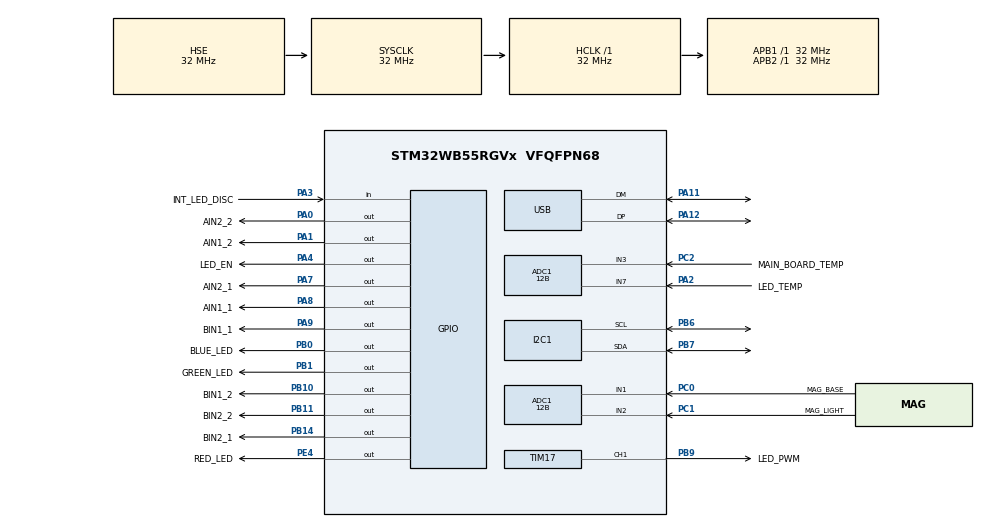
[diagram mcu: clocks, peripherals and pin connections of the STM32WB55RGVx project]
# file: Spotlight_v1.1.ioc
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ADC1.Channel-0\#ChannelRegularConversion=ADC_CHANNEL_1
ADC1.Channel-1\#ChannelRegularConversion=ADC_CHANNEL_2
ADC1.Channel-2\#ChannelRegularConversion=ADC_CHANNEL_3
ADC1.Channel-3\#ChannelRegularConversion=ADC_CHANNEL_7
ADC1.ClockPrescaler=ADC_CLOCK_ASYNC_DIV256
ADC1.ContinuousConvMode=ENABLE
ADC1.DMAContinuousRequests=ENABLE
ADC1.EOCSelection=ADC_EOC_SEQ_CONV
ADC1.NbrOfConversion=4
ADC1.NbrOfConversionFlag=1
ADC1.OffsetNumber-0\#ChannelRegularConversion=ADC_OFFSET_NONE
ADC1.OffsetNumber-1\#ChannelRegularConversion=ADC_OFFSET_NONE
ADC1.OffsetNumber-2\#ChannelRegularConversion=ADC_OFFSET_NONE
ADC1.OffsetNumber-3\#ChannelRegularConversion=ADC_OFFSET_NONE
ADC1.Overrun=ADC_OVR_DATA_OVERWRITTEN
ADC1.Rank-0\#ChannelRegularConversion=1
ADC1.Rank-1\#ChannelRegularConversion=2
ADC1.Rank-2\#ChannelRegularConversion=3
ADC1.Rank-3\#ChannelRegularConversion=4
ADC1.Resolution=ADC_RESOLUTION_12B
ADC1.SamplingTime-0\#ChannelRegularConversion=ADC_SAMPLETIME_24CYCLES_5
ADC1.SamplingTime-1\#ChannelRegularConversion=ADC_SAMPLETIME_24CYCLES_5
ADC1.SamplingTime-2\#ChannelRegularConversion=ADC_SAMPLETIME_24CYCLES_5
ADC1.SamplingTime-3\#ChannelRegularConversion=ADC_SAMPLETIME_24CYCLES_5
ADC1.master=1
Dma.ADC1.0.Direction=DMA_PERIPH_TO_MEMORY
Dma.ADC1.0.EventEnable=DISABLE
Dma.ADC1.0.Instance=DMA1_Channel1
Dma.ADC1.0.MemDataAlignment=DMA_MDATAALIGN_HALFWORD
Dma.ADC1.0.MemInc=DMA_MINC_ENABLE
Dma.ADC1.0.Mode=DMA_CIRCULAR
Dma.ADC1.0.PeriphDataAlignment=DMA_PDATAALIGN_HALFWORD
Dma.ADC1.0.PeriphInc=DMA_PINC_DISABLE
Dma.ADC1.0.Polarity=HAL_DMAMUX_REQ_GEN_RISING
Dma.ADC1.0.Priority=DMA_PRIORITY_LOW
Dma.ADC1.0.RequestNumber=1
Dma.ADC1.0.SignalID=NONE
Dma.ADC1.0.SyncEnable=DISABLE
Dma.ADC1.0.SyncPolarity=HAL_DMAMUX_SYNC_NO_EVENT
Dma.ADC1.0.SyncRequestNumber=1
Dma.ADC1.0.SyncSignalID=NONE
Dma.Request0=ADC1
FREERTOS.Tasks01=defaultTask,24,1024,StartDefaultTask,Default,NULL,Dynamic,NULL,NULL
FREERTOS.configMINIMAL_STACK_SIZE=512
FREERTOS.configTOTAL_HEAP_SIZE=10000
FREERTOS.configUSE_TICKLESS_IDLE=2
I2C1.Timing=0x00707CBB
Mcu.Family=STM32WB
Mcu.Name=STM32WB55RGVx
Mcu.Package=VFQFPN68
NVIC.ADC1_IRQn=true\:5\:0\:false\:false\:true\:true\:true\:true
NVIC.DMA1_Channel1_IRQn=true\:5\:0\:false\:false\:true\:true\:false\:true
NVIC.HSEM_IRQn=true\:5\:0\:false\:false\:true\:true\:false\:true
NVIC.PriorityGroup=NVIC_PRIORITYGROUP_4
NVIC.TIM1_UP_TIM16_IRQn=true\:0\:0\:false\:false\:true\:false\:false\:true
NVIC.TimeBase=TIM1_UP_TIM16_IRQn
NVIC.TimeBaseIP=TIM1
NVIC.USB_LP_IRQn=true\:5\:0\:false\:false\:true\:true\:false\:true
OSC_IN.Mode=HSE-External-Oscillator
OSC_IN.Signal=RCC_OSC_IN
OSC_OUT.Mode=HSE-External-Oscillator
OSC_OUT.Signal=RCC_OSC_OUT
PA0.GPIO_Label=AIN2_2
PA0.Signal=GPIO_Output
PA1.GPIO_Label=AIN1_2
PA1.Signal=GPIO_Output
PA11.GPIO_Speed=GPIO_SPEED_FREQ_VERY_HIGH
PA11.Mode=Device
PA11.Signal=USB_DM
PA12.GPIO_Speed=GPIO_SPEED_FREQ_VERY_HIGH
PA12.Mode=Device
PA12.Signal=USB_DP
PA13.Mode=Serial_Wire
PA13.Signal=SYS_JTMS-SWDIO
PA14.Mode=Serial_Wire
PA14.Signal=SYS_JTCK-SWCLK
PA2.GPIO_Label=LED_TEMP
PA2.Signal=ADCx_IN7
PA3.GPIO_Label=INT_LED_DISC
PA3.Signal=GPIO_Input
PA4.GPIO_Label=LED_EN
PA4.Signal=GPIO_Output
PA7.GPIO_Label=AIN2_1
PA7.Signal=GPIO_Output
PA8.GPIO_Label=AIN1_1
PA8.Signal=GPIO_Output
PA9.GPIO_Label=BIN1_1
PA9.Signal=GPIO_Output
PB0.GPIO_Label=BLUE_LED
PB0.PinState=GPIO_PIN_SET
PB0.Signal=GPIO_Output
PB1.GPIO_Label=GREEN_LED
PB1.PinState=GPIO_PIN_SET
PB1.Signal=GPIO_Output
PB10.GPIO_Label=BIN1_2
PB10.Signal=GPIO_Output
PB11.GPIO_Label=BIN2_2
PB11.Signal=GPIO_Output
PB14.GPIO_Label=BIN2_1
PB14.Signal=GPIO_Output
PB6.Mode=I2C
PB6.Signal=I2C1_SCL
PB7.Mode=I2C
PB7.Signal=I2C1_SDA
PB9.GPIO_Label=LED_PWM
PB9.Signal=S_TIM17_CH1
PC0.GPIO_Label=MAG_BASE
PC0.Signal=ADCx_IN1
PC1.GPIO_Label=MAG_LIGHT
PC1.Signal=ADCx_IN2
PC14-OSC32_IN.Mode=LSE-External-Oscillator
PC14-OSC32_IN.Signal=RCC_OSC32_IN
PC15-OSC32_OUT.Mode=LSE-External-Oscillator
PC15-OSC32_OUT.Signal=RCC_OSC32_OUT
PC2.GPIO_Label=MAIN_BOARD_TEMP
PC2.Signal=ADCx_IN3
PE4.GPIO_Label=RED_LED
PE4.PinState=GPIO_PIN_SET
PE4.Signal=GPIO_Output
ProjectManager.HeapSize=0x200
ProjectManager.StackSize=0x400
ProjectManager.TargetToolchain=STM32CubeIDE
RCC.ADCCLockSelection=RCC_ADCCLKSOURCE_SYSCLK
RCC.ADCFreq_Value=32000000
RCC.AHBFreq_Value=32000000
RCC.APB1Freq_Value=32000000
RCC.APB1TimFreq_Value=32000000
RCC.APB2Freq_Value=32000000
RCC.APB2TimFreq_Value=32000000
RCC.APB3Freq_Value=16000000
RCC.CortexFreq_Value=32000000
RCC.HCLKFreq_Value=32000000
RCC.HSE_VALUE=32000000
RCC.HSI48_VALUE=48000000
RCC.HSI_VALUE=16000000
RCC.PLLM=RCC_PLLM_DIV2
RCC.PLLSAI1N=6
RCC.PLLSourceVirtual=RCC_PLLSOURCE_HSE
RCC.RTCClockSelection=RCC_RTCCLKSOURCE_LSE
RCC.SYSCLKFreq_VALUE=32000000
RCC.SYSCLKSource=RCC_SYSCLKSOURCE_HSE
RCC.USBFreq_Value=48000000
RCC.VCOOutputFreq_Value=128000000
RF1.Mode=RF1_Activate
RF1.Signal=RF_RF1
SH.ADCx_IN1.0=ADC1_IN1,IN1-Single-Ended
SH.ADCx_IN2.0=ADC1_IN2,IN2-Single-Ended
SH.ADCx_IN3.0=ADC1_IN3,IN3-Single-Ended
SH.ADCx_IN7.0=ADC1_IN7,IN7-Single-Ended
SH.S_TIM17_CH1.0=TIM17_CH1,PWM Generation1 CH1
STM32_WPAN.APPLI_CONFIG_LOG_LEVEL=LOG_LEVEL_NONE
STM32_WPAN.CFG_DEBUGGER_SUPPORTED=1
STM32_WPAN.CFG_HW_RESET_BY_FW=1
STM32_WPAN.CHANNEL=23
STM32_WPAN.PANID=1234
STM32_WPAN.THREAD_APPLICATION=FTD
TIM17.AutoReloadPreload=TIM_AUTORELOAD_PRELOAD_DISABLE
TIM17.Channel=TIM_CHANNEL_1
TIM17.Period=100
TIM17.Prescaler=3199
TIM17.Pulse=1
TIM2.Prescaler=31
USB_DEVICE.CLASS_NAME_FS=CDC
USB_DEVICE.MANUFACTURER_STRING=RESENV
USB_DEVICE.PID_CDC_FS=0x5740
USB_DEVICE.PRODUCT_STRING_CDC_FS=SPOTLIGHT
USB_DEVICE.USBD_LPM_ENABLED=0
USB_DEVICE.VID=0x483
USB_DEVICE.VirtualMode=Cdc
USB_DEVICE.VirtualModeFS=Cdc_FS
VP_FREERTOS_VS_CMSIS_V2.Mode=CMSIS_V2
VP_HSEM_VS_HSEM.Mode=HSEM_Activate
VP_RTC_VS_RTC_Activate.Mode=RTC_Enabled
VP_STM32_WPAN_VS_THREAD.Mode=STM32_WPAN_Enabled
VP_SYS_VS_tim1.Mode=TIM1
VP_TIM17_VS_ClockSourceINT.Mode=Enable_Timer
VP_TIM2_VS_ClockSourceINT.Mode=Internal
VP_TINY_LPM_VS_TINY_LPM.Mode=TINY_LPM_Enabled
VP_USB_DEVICE_VS_USB_DEVICE_CDC_FS.Mode=CDC_FS
board=custom

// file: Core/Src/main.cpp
/* USER CODE BEGIN Header */
/**
  ******************************************************************************
  * @file           : main.c
  * @brief          : Main program body
  ******************************************************************************
  * @attention
  *
  * <h2><center>&copy; Copyright (c) 2020 STMicroelectronics.
  * All rights reserved.</center></h2>
  *
  * This software component is licensed by ST under Ultimate Liberty license
  * SLA0044, the "License"; You may not use this file except in compliance with
  * the License. You may obtain a copy of the License at:
  *                             www.st.com/SLA0044
  *
  ******************************************************************************
  */
/* USER CODE END Header */
#include "main.h"
#include "cmsis_os.h"
#include "adc.h"
#include "dma.h"
#include "rf.h"
#include "rtc.h"
#include "app_entry.h"
#include "app_common.h"
#include "tim.h"
#include "usb_device.h"
#include "gpio.h"
#include "i2c.h"

/* USER CODE BEGIN Includes */
//#include "stm32_seq.h"
#include "otp.h"
#include "stm32_lpm.h"
#include "dbg_trace.h"
#include "hw_conf.h"
#include "myMain.h"

/* USER CODE END Includes */

void SystemClock_Config(void);
void MX_FREERTOS_Init(void);

int main(void)
{
  /* USER CODE BEGIN 1 */
	  /**
	   * The OPTVERR flag is wrongly set at power on
	   * It shall be cleared before using any HAL_FLASH_xxx() api
	   */
	  __HAL_FLASH_CLEAR_FLAG(FLASH_FLAG_OPTVERR);
  /* USER CODE END 1 */

  /* MCU Configuration--------------------------------------------------------*/

  /* Reset of all peripherals, Initializes the Flash interface and the Systick. */
  HAL_Init();

  /* USER CODE BEGIN Init */
  Reset_Device();
  /* USER CODE END Init */

  /* Configure the system clock */
  SystemClock_Config();

  /* USER CODE BEGIN SysInit */
  Init_Exti( );
  initClk();
  /* USER CODE END SysInit */

  /* Initialize all configured peripherals */
  MX_GPIO_Init();
  MX_DMA_Init();
  MX_TIM2_Init();
  MX_TIM17_Init();
  MX_ADC1_Init();
  MX_USB_Device_Init();
  MX_RF_Init();
  MX_RTC_Init();
  MX_I2C1_Init();

  /* Init scheduler */
  osKernelInitialize();  /* Call init function for freertos objects (in freertos.c) */
  MX_FREERTOS_Init();
  /* Start scheduler */
  osKernelStart();

  /* We should never get here as control is now taken by the scheduler */
  /* Infinite loop */
  while (1)
  {

  }
}

void SystemClock_Config(void)
{
  RCC_OscInitTypeDef RCC_OscInitStruct = {0};
  RCC_ClkInitTypeDef RCC_ClkInitStruct = {0};
  RCC_PeriphCLKInitTypeDef PeriphClkInitStruct = {0};

  /** Macro to configure the PLL multiplication factor
  */
  __HAL_RCC_PLL_PLLM_CONFIG(RCC_PLLM_DIV2);
  /** Macro to configure the PLL clock source
  */
  __HAL_RCC_PLL_PLLSOURCE_CONFIG(RCC_PLLSOURCE_HSE);
  /** Configure LSE Drive Capability
  */
  HAL_PWR_EnableBkUpAccess();
  __HAL_RCC_LSEDRIVE_CONFIG(RCC_LSEDRIVE_LOW);
  /** Configure the main internal regulator output voltage
  */
  __HAL_PWR_VOLTAGESCALING_CONFIG(PWR_REGULATOR_VOLTAGE_SCALE1);
  /** Initializes the RCC Oscillators according to the specified parameters
  * in the RCC_OscInitTypeDef structure.
  */
  RCC_OscInitStruct.OscillatorType = RCC_OSCILLATORTYPE_HSI|RCC_OSCILLATORTYPE_HSE
                              |RCC_OSCILLATORTYPE_LSE;
  RCC_OscInitStruct.HSEState = RCC_HSE_ON;
  RCC_OscInitStruct.LSEState = RCC_LSE_ON;
  RCC_OscInitStruct.HSIState = RCC_HSI_ON;
  RCC_OscInitStruct.HSICalibrationValue = RCC_HSICALIBRATION_DEFAULT;
  RCC_OscInitStruct.PLL.PLLState = RCC_PLL_NONE;
  if (HAL_RCC_OscConfig(&RCC_OscInitStruct) != HAL_OK)
  {
    Error_Handler();
  }
  /** Configure the SYSCLKSource, HCLK, PCLK1 and PCLK2 clocks dividers
  */
  RCC_ClkInitStruct.ClockType = RCC_CLOCKTYPE_HCLK4|RCC_CLOCKTYPE_HCLK2
                              |RCC_CLOCKTYPE_HCLK|RCC_CLOCKTYPE_SYSCLK
                              |RCC_CLOCKTYPE_PCLK1|RCC_CLOCKTYPE_PCLK2;
  RCC_ClkInitStruct.SYSCLKSource = RCC_SYSCLKSOURCE_HSE;
  RCC_ClkInitStruct.AHBCLKDivider = RCC_SYSCLK_DIV1;
  RCC_ClkInitStruct.APB1CLKDivider = RCC_HCLK_DIV1;
  RCC_ClkInitStruct.APB2CLKDivider = RCC_HCLK_DIV1;
  RCC_ClkInitStruct.AHBCLK2Divider = RCC_SYSCLK_DIV1;
  RCC_ClkInitStruct.AHBCLK4Divider = RCC_SYSCLK_DIV1;

  if (HAL_RCC_ClockConfig(&RCC_ClkInitStruct, FLASH_LATENCY_1) != HAL_OK)
  {
    Error_Handler();
  }
  /** Initializes the peripherals clocks
  */
  PeriphClkInitStruct.PeriphClockSelection = RCC_PERIPHCLK_SMPS|RCC_PERIPHCLK_RFWAKEUP
                              |RCC_PERIPHCLK_RTC|RCC_PERIPHCLK_USB
                              |RCC_PERIPHCLK_ADC;
  PeriphClkInitStruct.PLLSAI1.PLLN = 6;
  PeriphClkInitStruct.PLLSAI1.PLLP = RCC_PLLP_DIV2;
  PeriphClkInitStruct.PLLSAI1.PLLQ = RCC_PLLQ_DIV2;
  PeriphClkInitStruct.PLLSAI1.PLLR = RCC_PLLR_DIV2;
  PeriphClkInitStruct.PLLSAI1.PLLSAI1ClockOut = RCC_PLLSAI1_USBCLK;
  PeriphClkInitStruct.UsbClockSelection = RCC_USBCLKSOURCE_PLLSAI1;
  PeriphClkInitStruct.AdcClockSelection = RCC_ADCCLKSOURCE_SYSCLK;
  PeriphClkInitStruct.RTCClockSelection = RCC_RTCCLKSOURCE_LSE;
  PeriphClkInitStruct.RFWakeUpClockSelection = RCC_RFWKPCLKSOURCE_HSE_DIV1024;
  PeriphClkInitStruct.SmpsClockSelection = RCC_SMPSCLKSOURCE_HSI;
  PeriphClkInitStruct.SmpsDivSelection = RCC_SMPSCLKDIV_RANGE1;
  if (HAL_RCCEx_PeriphCLKConfig(&PeriphClkInitStruct) != HAL_OK)
  {
    Error_Handler();
  }
  /* USER CODE BEGIN Smps */

  //https://community.st.com/s/question/0D50X0000C0wdqe/stm32wb55-ble-hid?t=1591239574627
  LL_HSEM_1StepLock(HSEM, 5 );
  LL_RCC_HSI48_Enable();
  while(!LL_RCC_HSI48_IsReady());
  /* USER CODE END Smps */
}

 /**
  * @brief  Period elapsed callback in non blocking mode
  * @note   This function is called  when TIM1 interrupt took place, inside
  * HAL_TIM_IRQHandler(). It makes a direct call to HAL_IncTick() to increment
  * a global variable "uwTick" used as application time base.
  * @param  htim : TIM handle
  * @retval None
  */
void HAL_TIM_PeriodElapsedCallback(TIM_HandleTypeDef *htim)
{
  if (htim->Instance == TIM1) {
    HAL_IncTick();
  }
}

void Error_Handler(void)
{
  __disable_irq();
  while (1)
  {
  }
}

/************************ (C) COPYRIGHT STMicroelectronics *****END OF FILE****/
